# MKE16Z4 register map
Vendor: nxp.com; File version: 1.0
MKE16Z32VLD4,MKE16Z32VLF4,MKE16Z64VLD4,MKE16Z64VLF4
CPU: CM0PLUS r0p0, little endian, no MPU, no FPU, VTOR, 2 interrupt priority bits
Registers are 32-bit, read-write, reset 0x0 unless marked. A register's access mark holds for its fields unless they carry their own. Offsets are from the block's base; lines under a group give offsets from that group; [hi:lo] are bit positions; {n}, {i} and the like mark numbered series; 'fields as' and 'values as' point back to an identical list; <NAME> marks a mode.

## Memory map
0x00000400 FTFA_FlashConfig size 0xE — Flash configuration field
0x40020000 FTFA size 0x14 — Flash Memory Interface
0x40024000 MSCAN size 0x40 — Modular/Scalable Controller Area Network (MSCAN)
0x4002C000 LPSPI0 size 0x78 — The LPSPI Memory Map/Register Definition can be found here.
0x40032000 CRC size 0xC — Cyclic Redundancy Check
0x40036000 PDB0 size 0x198 — Programmable Delay Block
0x40037000 LPIT0 size 0x3C — Low Power Periodic Interrupt Timer (LPIT)
0x40038000 FTM0 size 0x21C — FlexTimer Module
0x40039000 FTM1 size 0x21C — FlexTimer Module
0x4003B000 ADC0 size 0xEC — Analog-to-Digital Converter
0x4003D000 RTC size 0x808 — Secure Real Time Clock
0x40040000 LPTMR0 size 0x10 — Low Power Timer
0x40045000 TSI size 0x28 — Touch sense input
0x40048000 SIM size 0x70 — System Integration Module
0x40049000 PORTA size 0xCC — Pin Control and Interrupts
0x4004A000 PORTB size 0xCC — Pin Control and Interrupts
0x4004B000 PORTC size 0xCC — Pin Control and Interrupts
0x4004C000 PORTD size 0xCC — Pin Control and Interrupts
0x4004D000 PORTE size 0xCC — Pin Control and Interrupts
0x40052000 WDOG size 0x10 — Watchdog timer
0x40056000 PWT size 0x8 — Pulse Width Timer
0x40061000 EWM size 0x6 — External Watchdog Monitor
0x40062000 TRGMUX0 size 0x70 — Trigger MUX Control
0x40063000 TRGMUX1 size 0x4 — Trigger MUX Control
0x40064000 SCG size 0x518 — System Clock Generator
0x40065000 PCC size 0x1D0
0x40066000 LPI2C0 size 0x174 — The LPI2C Memory Map/Register Definition can be found here.
0x4006A000 LPUART0 size 0x30 — Low Power Universal Asynchronous Receiver/Transmitter
0x4006B000 LPUART1 size 0x30 — Low Power Universal Asynchronous Receiver/Transmitter
0x4006C000 LPUART2 size 0x30 — Low Power Universal Asynchronous Receiver/Transmitter
0x40073000 CMP0 size 0xC — High-Speed Comparator (CMP), Voltage Reference (VREF) Digital-to-Analog Converter (DAC), and Analog Mux (ANMUX)
0x4007D000 PMC size 0x5
0x4007E000 SMC size 0x18 — System Mode Controller
0x4007F000 RCM size 0x20 — Reset Control Module
0x400FF000 GPIOA size 0x18 — General Purpose Input/Output
0x400FF040 GPIOB size 0x18 — General Purpose Input/Output
0x400FF080 GPIOC size 0x18 — General Purpose Input/Output
0x400FF0C0 GPIOD size 0x18 — General Purpose Input/Output
0x400FF100 GPIOE size 0x18 — General Purpose Input/Output
0xF0000000 MTB size 0x1000 — Micro Trace Buffer
0xF0001000 MTBDWT size 0x1000 — MTB data watchpoint and trace
0xF0002000 ROM size 0x1000 — System ROM
0xF0003000 MCM size 0x44 — Core Platform Miscellaneous Control Module
0xF0004000 MMDVSQ size 0x14 — Divide and Square Root
0xF8000000 FGPIOA size 0x18 — General Purpose Input/Output
0xF8000040 FGPIOB size 0x18 — General Purpose Input/Output
0xF8000080 FGPIOC size 0x18 — General Purpose Input/Output
0xF80000C0 FGPIOD size 0x18 — General Purpose Input/Output
0xF8000100 FGPIOE size 0x18 — General Purpose Input/Output

## Interrupts
5 FTFA
6 LVD_LVW (PMC)
7 PORTAE (PORTA, PORTE, GPIOA, GPIOE)
8 LPI2C0
10 LPSPI0
12 LPUART0
13 LPUART1
14 LPUART2
15 ADC0
16 CMP0
17 FTM0
18 FTM1
20 RTC
22 LPIT0
24 TSI
25 PDB0
26 PORTBCD (PORTB, PORTC, PORTD, GPIOB, GPIOC, GPIOD)
27 SCG_RCM (SCG, RCM)
28 WDOG_EWM (WDOG, EWM)
29 PWT_LPTMR0 (LPTMR0, PWT)
30 MSCAN_Rx (MSCAN)
31 MSCAN_ORed (MSCAN)

## FTFA_FlashConfig — Flash configuration field
Base 0x00000400; register names take the prefix NV_
0x00 BACKKEY3 8-bit ro reset 0xFF — Backdoor Comparison Key 3.
  [7:0] KEY — Backdoor Comparison Key.
0x01 BACKKEY2 8-bit ro reset 0xFF — Backdoor Comparison Key 2.
  [7:0] KEY — Backdoor Comparison Key.
0x02 BACKKEY1 8-bit ro reset 0xFF — Backdoor Comparison Key 1.
  [7:0] KEY — Backdoor Comparison Key.
0x03 BACKKEY0 8-bit ro reset 0xFF — Backdoor Comparison Key 0.
  [7:0] KEY — Backdoor Comparison Key.
0x04 BACKKEY7 8-bit ro reset 0xFF — Backdoor Comparison Key 7.
  [7:0] KEY — Backdoor Comparison Key.
0x05 BACKKEY6 8-bit ro reset 0xFF — Backdoor Comparison Key 6.
  [7:0] KEY — Backdoor Comparison Key.
0x06 BACKKEY5 8-bit ro reset 0xFF — Backdoor Comparison Key 5.
  [7:0] KEY — Backdoor Comparison Key.
0x07 BACKKEY4 8-bit ro reset 0xFF — Backdoor Comparison Key 4.
  [7:0] KEY — Backdoor Comparison Key.
0x08 FPROT3 8-bit ro reset 0xFF — Non-volatile P-Flash Protection 1 - Low Register
  [7:0] PROT — P-Flash Region Protect
0x09 FPROT2 8-bit ro reset 0xFF — Non-volatile P-Flash Protection 1 - High Register
  [7:0] PROT — P-Flash Region Protect
0x0A FPROT1 8-bit ro reset 0xFF — Non-volatile P-Flash Protection 0 - Low Register
  [7:0] PROT — P-Flash Region Protect
0x0B FPROT0 8-bit ro reset 0xFF — Non-volatile P-Flash Protection 0 - High Register
  [7:0] PROT — P-Flash Region Protect
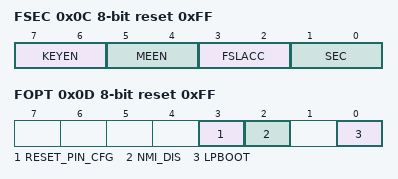
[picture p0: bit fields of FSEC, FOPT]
0x0C FSEC 8-bit ro reset 0xFF — Non-volatile Flash Security Register
  [7:6] KEYEN — Backdoor Key Security Enable
    2=Backdoor key access enabled; 3=Backdoor key access disabled
  [5:4] MEEN
    2=Mass erase is disabled; 3=Mass erase is enabled
  [3:2] FSLACC — Freescale Failure Analysis Access Code
    2=Freescale factory access denied; 3=Freescale factory access granted
  [1:0] SEC — Flash Security
    2=MCU security status is unsecure; 3=MCU security status is secure
0x0D FOPT 8-bit ro reset 0xFF — Non-volatile Flash Option Register
  [3] RESET_PIN_CFG
    0=RESET pin is disabled following a POR and cannot be enabled as reset function; 1=RESET_b pin is dedicated
  [2] NMI_DIS
    0=NMI interrupts are always blocked; 1=NMI_b pin/interrupts reset default to enabled
  [0] LPBOOT
    0=Low-power boot; 1=Normal boot

## Licence text in the file
Copyright 2016-2020 NXP All rights reserved. SPDX-License-Identifier: BSD-3-Clause
